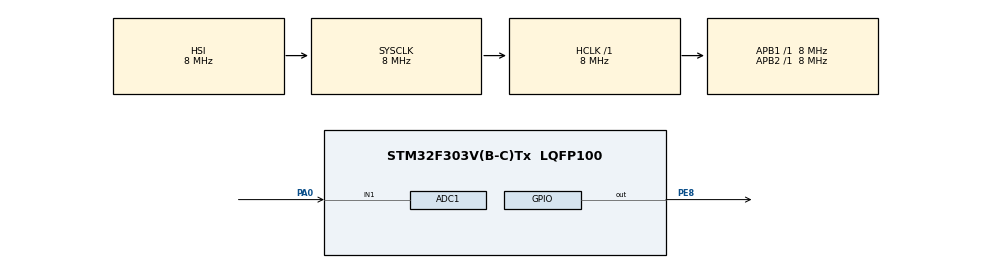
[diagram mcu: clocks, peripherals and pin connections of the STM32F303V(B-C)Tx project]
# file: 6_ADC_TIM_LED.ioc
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ADC1.Channel-0\#ChannelRegularConversion=ADC_CHANNEL_1
ADC1.ClockPrescaler=ADC_CLOCK_SYNC_PCLK_DIV4
ADC1.ExternalTrigConv=ADC_EXTERNALTRIGCONV_T2_TRGO
ADC1.InjNumberOfConversion=0
ADC1.NbrOfConversion=1
ADC1.NbrOfConversionFlag=1
ADC1.Offset-0\#ChannelRegularConversion=0
ADC1.OffsetNumber-0\#ChannelRegularConversion=ADC_OFFSET_NONE
ADC1.Rank-0\#ChannelRegularConversion=1
ADC1.Resolution=ADC_RESOLUTION_8B
ADC1.SamplingTime-0\#ChannelRegularConversion=ADC_SAMPLETIME_181CYCLES_5
ADC1.master=1
Mcu.Family=STM32F3
Mcu.Name=STM32F303V(B-C)Tx
Mcu.Package=LQFP100
NVIC.ADC1_2_IRQn=true\:0\:0\:false\:false\:true\:true
NVIC.PriorityGroup=NVIC_PRIORITYGROUP_4
PA0.Mode=IN1-Single-Ended
PA0.Signal=ADC1_IN1
PE8.Signal=GPIO_Output
ProjectManager.HeapSize=0x200
ProjectManager.StackSize=0x400
ProjectManager.TargetToolchain=MDK-ARM V5
RCC.AHBFreq_Value=8000000
RCC.APB1Freq_Value=8000000
RCC.APB2Freq_Value=8000000
RCC.CortexFreq_Value=8000000
RCC.HSE_VALUE=8000000
RCC.HSI_VALUE=8000000
RCC.LSE_VALUE=32768
RCC.PLLMUL=RCC_PLL_MUL4
RCC.SYSCLKFreq_VALUE=8000000
RCC.USBFreq_Value=16000000
TIM2.Period=100
TIM2.Prescaler=8000
TIM2.TIM_MasterOutputTrigger=TIM_TRGO_UPDATE
VP_TIM2_VS_ClockSourceINT.Mode=Internal
board=6_ADC_TIM_LED

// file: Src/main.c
/**
  ******************************************************************************
  * File Name          : main.c
  * Description        : Main program body
  ******************************************************************************
  ** This notice applies to any and all portions of this file
  * that are not between comment pairs USER CODE BEGIN and
  * USER CODE END. Other portions of this file, whether
  * inserted by the user or by software development tools
  * are owned by their respective copyright owners.
  *
  * COPYRIGHT(c) 2022 STMicroelectronics
  *
  * Redistribution and use in source and binary forms, with or without modification,
  * are permitted provided that the following conditions are met:
  *   1. Redistributions of source code must retain the above copyright notice,
  *      this list of conditions and the following disclaimer.
  *   2. Redistributions in binary form must reproduce the above copyright notice,
  *      this list of conditions and the following disclaimer in the documentation
  *      and/or other materials provided with the distribution.
  *   3. Neither the name of STMicroelectronics nor the names of its contributors
  *      may be used to endorse or promote products derived from this software
  *      without specific prior written permission.
  *
  * THIS SOFTWARE IS PROVIDED BY THE COPYRIGHT HOLDERS AND CONTRIBUTORS "AS IS"
  * AND ANY EXPRESS OR IMPLIED WARRANTIES, INCLUDING, BUT NOT LIMITED TO, THE
  * IMPLIED WARRANTIES OF MERCHANTABILITY AND FITNESS FOR A PARTICULAR PURPOSE ARE
  * DISCLAIMED. IN NO EVENT SHALL THE COPYRIGHT HOLDER OR CONTRIBUTORS BE LIABLE
  * FOR ANY DIRECT, INDIRECT, INCIDENTAL, SPECIAL, EXEMPLARY, OR CONSEQUENTIAL
  * DAMAGES (INCLUDING, BUT NOT LIMITED TO, PROCUREMENT OF SUBSTITUTE GOODS OR
  * SERVICES; LOSS OF USE, DATA, OR PROFITS; OR BUSINESS INTERRUPTION) HOWEVER
  * CAUSED AND ON ANY THEORY OF LIABILITY, WHETHER IN CONTRACT, STRICT LIABILITY,
  * OR TORT (INCLUDING NEGLIGENCE OR OTHERWISE) ARISING IN ANY WAY OUT OF THE USE
  * OF THIS SOFTWARE, EVEN IF ADVISED OF THE POSSIBILITY OF SUCH DAMAGE.
  *
  ******************************************************************************
  */

#include "main.h"
#include "stm32f3xx_hal.h"
#include "adc.h"
#include "tim.h"
#include "gpio.h"

/* USER CODE BEGIN PV */
/* Private variables ---------------------------------------------------------*/

/* USER CODE END PV */

void SystemClock_Config(void);

/* USER CODE BEGIN PFP */
/* Private function prototypes -----------------------------------------------*/

/* USER CODE END PFP */

/* USER CODE BEGIN 0 */

uint8_t valor_adc = 0;

/* USER CODE END 0 */

int main(void)
{

  /* MCU Configuration----------------------------------------------------------*/

  /* Reset of all peripherals, Initializes the Flash interface and the Systick. */
  HAL_Init();

  /* Configure the system clock */
  SystemClock_Config();

  /* Initialize all configured peripherals */
  MX_GPIO_Init();
  MX_ADC1_Init();
  MX_TIM2_Init();

  /* USER CODE BEGIN 2 */

	HAL_TIM_Base_Start(&htim2); // Activamos el timer2
	HAL_ADC_Start_IT(&hadc1); // Iniciamos el adc con la interrupciСn
  /* USER CODE END 2 */

  /* Infinite loop */
  while (1)
  {

  }

}

/** System Clock Configuration
*/
void SystemClock_Config(void)
{

  RCC_OscInitTypeDef RCC_OscInitStruct;
  RCC_ClkInitTypeDef RCC_ClkInitStruct;

    /**Initializes the CPU, AHB and APB busses clocks
    */
  RCC_OscInitStruct.OscillatorType = RCC_OSCILLATORTYPE_HSI;
  RCC_OscInitStruct.HSIState = RCC_HSI_ON;
  RCC_OscInitStruct.HSICalibrationValue = 16;
  RCC_OscInitStruct.PLL.PLLState = RCC_PLL_NONE;
  if (HAL_RCC_OscConfig(&RCC_OscInitStruct) != HAL_OK)
  {
    _Error_Handler(__FILE__, __LINE__);
  }

    /**Initializes the CPU, AHB and APB busses clocks
    */
  RCC_ClkInitStruct.ClockType = RCC_CLOCKTYPE_HCLK|RCC_CLOCKTYPE_SYSCLK
                              |RCC_CLOCKTYPE_PCLK1|RCC_CLOCKTYPE_PCLK2;
  RCC_ClkInitStruct.SYSCLKSource = RCC_SYSCLKSOURCE_HSI;
  RCC_ClkInitStruct.AHBCLKDivider = RCC_SYSCLK_DIV1;
  RCC_ClkInitStruct.APB1CLKDivider = RCC_HCLK_DIV1;
  RCC_ClkInitStruct.APB2CLKDivider = RCC_HCLK_DIV1;

  if (HAL_RCC_ClockConfig(&RCC_ClkInitStruct, FLASH_LATENCY_0) != HAL_OK)
  {
    _Error_Handler(__FILE__, __LINE__);
  }

    /**Configure the Systick interrupt time
    */
  HAL_SYSTICK_Config(HAL_RCC_GetHCLKFreq()/1000);

    /**Configure the Systick
    */
  HAL_SYSTICK_CLKSourceConfig(SYSTICK_CLKSOURCE_HCLK);

  /* SysTick_IRQn interrupt configuration */
  HAL_NVIC_SetPriority(SysTick_IRQn, 0, 0);
}

/* USER CODE BEGIN 4 */
void HAL_ADC_ConvCpltCallback(ADC_HandleTypeDef* hadc)
{
  /* Prevent unused argument(s) compilation warning */
  UNUSED(hadc);

  /* NOTE : This function should not be modified. When the callback is needed,
            function HAL_ADC_ConvCpltCallback must be implemented in the user file.
   */
	valor_adc = HAL_ADC_GetValue(&hadc1);
	HAL_GPIO_TogglePin(GPIOE, GPIO_PIN_8);
}
/* USER CODE END 4 */

void _Error_Handler(char * file, int line)
{
  while(1)
  {
  }
}

/************************ (C) COPYRIGHT STMicroelectronics *****END OF FILE****/
